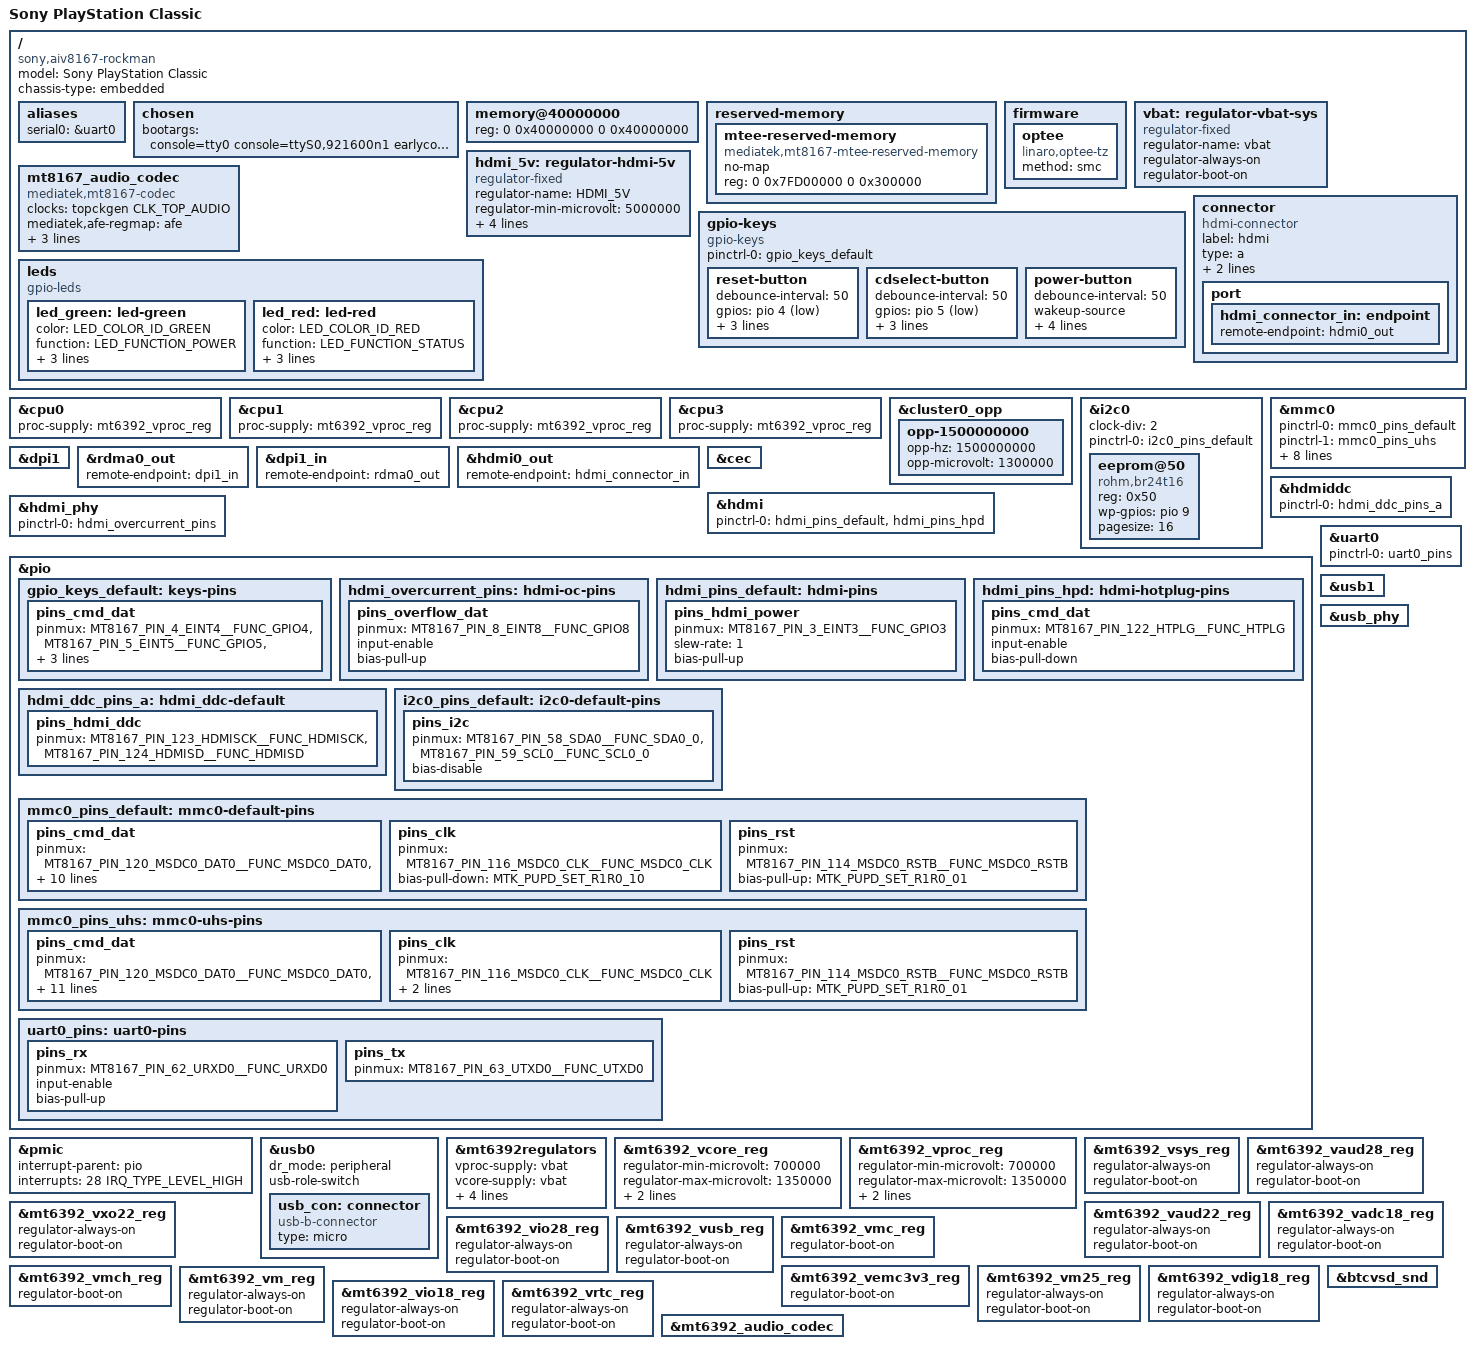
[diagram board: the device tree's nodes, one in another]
// SPDX-License-Identifier: GPL-2.0
/dts-v1/;
#include <dt-bindings/gpio/gpio.h>
#include <dt-bindings/input/linux-event-codes.h>
#include <dt-bindings/leds/common.h>
#include "mt8167.dtsi"
#include "mt6392.dtsi"

/ {
	model = "Sony PlayStation Classic";
	chassis-type = "embedded";
	compatible = "sony,aiv8167-rockman", "mediatek,mt8167";

	aliases {
		serial0 = &uart0;
	};

	chosen {
		#address-cells = <2>;
		#size-cells = <2>;
		bootargs = "console=tty0 console=ttyS0,921600n1 earlycon=uart8250,mmio32,0x11005000 root=/dev/ram0 initrd=0x42200000,4M";
		ranges;
	};

	memory@40000000 {
		device_type = "memory";
		reg = <0 0x40000000 0 0x40000000>;
	};

	reserved-memory {
		#address-cells = <2>;
		#size-cells = <2>;
		ranges;

		/*
		If you modify the memory size,please modify mtee-reserved-memory size together.
		mtee must be located begin with the last 3MB of dram
		*/
		mtee-reserved-memory {
			compatible = "mediatek,mt8167-mtee-reserved-memory";
			no-map;
			reg = <0 0x7FD00000 0 0x300000>;
		};
	};

	firmware {
		optee {
			compatible = "linaro,optee-tz";
			method = "smc";
		};
	};

	vbat: regulator-vbat-sys {
		compatible = "regulator-fixed";
		regulator-name = "vbat";
		regulator-always-on;
		regulator-boot-on;
	};

	hdmi_5v: regulator-hdmi-5v {
		compatible = "regulator-fixed";

		regulator-name = "HDMI_5V";
		regulator-min-microvolt = <5000000>;
		regulator-max-microvolt = <5000000>;

		gpio = <&pio 3 GPIO_ACTIVE_HIGH>;
		enable-active-high;
		regulator-always-on;
	};

	mt8167_audio_codec: mt8167_audio_codec {
		compatible = "mediatek,mt8167-codec";
		clocks = <&topckgen CLK_TOP_AUDIO>;
		clock-names = "bus";
		mediatek,afe-regmap = <&afe>;
		mediatek,apmixedsys-regmap = <&apmixedsys>;
		mediatek,dmic-wire-mode = <1>; /* 0(ONE_WIRE) 1(TWO_WIRE) */
		mediatek,headphone-cap-sel = <1>; /* 0(10UF) 1(22UF) 2(33UF) 3(47UF) */
	};

	/*sound {
		compatible = "mediatek,mt8167s-es7243";
		mediatek,platform = <&afe>;
		pinctrl-0 = <&aud_default_pins>;
		pinctrl-1 = <&aud_extamp_on_pins>;
		pinctrl-2 = <&aud_extamp_off_pins>;
		pinctrl-names = "default", "extamp_on", "extamp_off";
		tdmadc-3p3v-supply = <&mt6392_vmch_reg>;
		tdmadc-1p8v-supply = <&mt6392_vcamio_reg>;
	};*/

	/*extcon_usb: extcon_iddig {
		compatible = "linux,extcon-usb-gpio";
		id-gpios = <&pio 41 GPIO_ACTIVE_HIGH>;
	};*/

	gpio-keys {
		compatible = "gpio-keys";
		pinctrl-names = "default";
		pinctrl-0 = <&gpio_keys_default>;

		reset-button {
			debounce-interval = <50>;
			gpios = <&pio 4 GPIO_ACTIVE_LOW>;
			label = "playpause";
			linux,input-type = <EV_KEY>;
			linux,code = <KEY_PLAYPAUSE>;
		};

		cdselect-button {
			debounce-interval = <50>;
			gpios = <&pio 5 GPIO_ACTIVE_LOW>;
			label = "cdselect";
			linux,input-type = <EV_KEY>;
			linux,code = <KEY_EJECTCD>;
		};

		power-button {
			debounce-interval = <50>;
			wakeup-source;
			gpios = <&pio 10 GPIO_ACTIVE_LOW>;
			label = "sleep";
			linux,input-type = <EV_KEY>;
			linux,code = <KEY_SLEEP>;
		};
	};

	leds {
		compatible = "gpio-leds";

		led_green: led-green {
			color = <LED_COLOR_ID_GREEN>;
			function = LED_FUNCTION_POWER;
			gpios = <&pio 12 GPIO_ACTIVE_HIGH>;
			default-state = "off";
			retain-state-suspended;
		};

		led_red: led-red {
			color = <LED_COLOR_ID_RED>;
			function = LED_FUNCTION_STATUS;
			gpios = <&pio 0 GPIO_ACTIVE_HIGH>;
			default-state = "off";
			retain-state-suspended;
		};
	};

	connector {
		compatible = "hdmi-connector";
		label = "hdmi";

		type = "a";
		ddc-i2c-bus = <&hdmiddc>;
		hpd-gpios = <&pio 122 GPIO_ACTIVE_HIGH>;

		port {
			hdmi_connector_in: endpoint {
				remote-endpoint = <&hdmi0_out>;
			};
		};
	};
};

/* With the firmware on Android devices, cores don't seem to come back after out
   idle/unplug (though initial SMP boot is fine) */

&cpu0 {
	/delete-property/ cpu-idle-states;
	proc-supply = <&mt6392_vproc_reg>;
};

&cpu1 {
	/delete-property/ cpu-idle-states;
	proc-supply = <&mt6392_vproc_reg>;
};

&cpu2 {
	/delete-property/ cpu-idle-states;
	proc-supply = <&mt6392_vproc_reg>;
};

&cpu3 {
	/delete-property/ cpu-idle-states;
	proc-supply = <&mt6392_vproc_reg>;
};

&cluster0_opp {
	opp-1500000000 {
		opp-hz = /bits/ 64 <1500000000>;
		opp-microvolt = <1300000>;
	};
};

&i2c0 {
	clock-div = <2>;
	pinctrl-names = "default";
	pinctrl-0 = <&i2c0_pins_default>;
	status = "okay";

	eeprom@50 {
		reg = <0x50>;
		compatible = "rohm,br24t16", "atmel,24c16";
		wp-gpios = <&pio 9 GPIO_ACTIVE_HIGH>;
		pagesize = <16>;
	};
};

&mmc0 {
	status = "okay";

	pinctrl-names = "default", "state_uhs";
	pinctrl-0 = <&mmc0_pins_default>;
	pinctrl-1 = <&mmc0_pins_uhs>;

	bus-width = <8>;
	max-frequency = <200000000>;
	cap-mmc-highspeed;
	mmc-hs200-1_8v;
	cap-mmc-hw-reset;
	non-removable;

	vmmc-supply = <&mt6392_vemc3v3_reg>;
	vqmmc-supply = <&mt6392_vio18_reg>;
};

&dpi1 {
	status = "okay";
};

&rdma0_out {
	remote-endpoint = <&dpi1_in>;
};

&dpi1_in {
	remote-endpoint = <&rdma0_out>;
};

&hdmi0_out {
	remote-endpoint = <&hdmi_connector_in>;
};

&cec {
	status = "okay";
};

&hdmi {
	status = "okay";
	pinctrl-names = "default";
	pinctrl-0 = <&hdmi_pins_default>, <&hdmi_pins_hpd>;
};

&hdmiddc {
	status = "okay";
	pinctrl-names = "default";
	pinctrl-0 = <&hdmi_ddc_pins_a>;
};

&hdmi_phy {
	status = "okay";
	pinctrl-names = "default";
	pinctrl-0 = <&hdmi_overcurrent_pins>;
};

&pio {
	pinctrl-names = "default";
	/*pinctrl-0 = <&state_default>;*/

	/*state_default: default-pins {
		pins_cmd_dat1 {
			pinmux = <MT8167_PIN_1_EINT1__FUNC_GPIO1>,
				 <MT8167_PIN_2_EINT2__FUNC_GPIO2>;
			input-enable;
			bias-disable;
		};

		pins_cmd_dat2 {
			pinmux = <MT8167_PIN_6_EINT6__FUNC_GPIO6>,
				 <MT8167_PIN_7_EINT7__FUNC_GPIO7>;
			input-enable;
			bias-pull-up;
		};
	};*/

	gpio_keys_default: keys-pins {
		pins_cmd_dat {
			pinmux = <MT8167_PIN_4_EINT4__FUNC_GPIO4>,
				 <MT8167_PIN_5_EINT5__FUNC_GPIO5>,
				 <MT8167_PIN_10_EINT10__FUNC_GPIO10>;
			bias-pull-up;
			input-enable;
		};
	};

	hdmi_overcurrent_pins: hdmi-oc-pins {
		pins_overflow_dat {
			pinmux = <MT8167_PIN_8_EINT8__FUNC_GPIO8>;
			input-enable;
			bias-pull-up;
		};
	};

	hdmi_pins_default: hdmi-pins {
		pins_hdmi_power {
			pinmux = <MT8167_PIN_3_EINT3__FUNC_GPIO3>;
			slew-rate = <1>;
			bias-pull-up;
		};
	};

	hdmi_pins_hpd: hdmi-hotplug-pins {
		pins_cmd_dat {
			pinmux = <MT8167_PIN_122_HTPLG__FUNC_HTPLG>;
			input-enable;
			bias-pull-down;
		};
	};

	hdmi_ddc_pins_a: hdmi_ddc-default {
		pins_hdmi_ddc {
			pinmux = <MT8167_PIN_123_HDMISCK__FUNC_HDMISCK>,
				 <MT8167_PIN_124_HDMISD__FUNC_HDMISD>;
		};
	};

	i2c0_pins_default: i2c0-default-pins {
		pins_i2c {
			pinmux = <MT8167_PIN_58_SDA0__FUNC_SDA0_0>,
				 <MT8167_PIN_59_SCL0__FUNC_SCL0_0>;
			bias-disable;
		};
	};

	mmc0_pins_default: mmc0-default-pins {
		pins_cmd_dat {
			pinmux = <MT8167_PIN_120_MSDC0_DAT0__FUNC_MSDC0_DAT0>,
				 <MT8167_PIN_119_MSDC0_DAT1__FUNC_MSDC0_DAT1>,
				 <MT8167_PIN_118_MSDC0_DAT2__FUNC_MSDC0_DAT2>,
				 <MT8167_PIN_117_MSDC0_DAT3__FUNC_MSDC0_DAT3>,
				 <MT8167_PIN_113_MSDC0_DAT4__FUNC_MSDC0_DAT4>,
				 <MT8167_PIN_112_MSDC0_DAT5__FUNC_MSDC0_DAT5>,
				 <MT8167_PIN_111_MSDC0_DAT6__FUNC_MSDC0_DAT6>,
				 <MT8167_PIN_110_MSDC0_DAT7__FUNC_MSDC0_DAT7>,
				 <MT8167_PIN_115_MSDC0_CMD__FUNC_MSDC0_CMD>;
			input-enable;
			bias-pull-up = <MTK_PUPD_SET_R1R0_01>;
		};

		pins_clk {
			pinmux = <MT8167_PIN_116_MSDC0_CLK__FUNC_MSDC0_CLK>;
			bias-pull-down = <MTK_PUPD_SET_R1R0_10>;
		};

		pins_rst {
			pinmux = <MT8167_PIN_114_MSDC0_RSTB__FUNC_MSDC0_RSTB>;
			bias-pull-up = <MTK_PUPD_SET_R1R0_01>;
		};
	};

	mmc0_pins_uhs: mmc0-uhs-pins {
		pins_cmd_dat {
			pinmux = <MT8167_PIN_120_MSDC0_DAT0__FUNC_MSDC0_DAT0>,
				 <MT8167_PIN_119_MSDC0_DAT1__FUNC_MSDC0_DAT1>,
				 <MT8167_PIN_118_MSDC0_DAT2__FUNC_MSDC0_DAT2>,
				 <MT8167_PIN_117_MSDC0_DAT3__FUNC_MSDC0_DAT3>,
				 <MT8167_PIN_113_MSDC0_DAT4__FUNC_MSDC0_DAT4>,
				 <MT8167_PIN_112_MSDC0_DAT5__FUNC_MSDC0_DAT5>,
				 <MT8167_PIN_111_MSDC0_DAT6__FUNC_MSDC0_DAT6>,
				 <MT8167_PIN_110_MSDC0_DAT7__FUNC_MSDC0_DAT7>,
				 <MT8167_PIN_115_MSDC0_CMD__FUNC_MSDC0_CMD>;
			input-enable;
			drive-strength = <MTK_DRIVE_6mA>;
			bias-pull-up = <MTK_PUPD_SET_R1R0_01>;
		};

		pins_clk {
			pinmux = <MT8167_PIN_116_MSDC0_CLK__FUNC_MSDC0_CLK>;
			drive-strength = <MTK_DRIVE_8mA>;
			bias-pull-down = <MTK_PUPD_SET_R1R0_10>;
		};

		pins_rst {
			pinmux = <MT8167_PIN_114_MSDC0_RSTB__FUNC_MSDC0_RSTB>;
			bias-pull-up = <MTK_PUPD_SET_R1R0_01>;
		};
	};

	uart0_pins: uart0-pins {
		pins_rx {
			pinmux = <MT8167_PIN_62_URXD0__FUNC_URXD0>;
			input-enable;
			bias-pull-up;
		};
		pins_tx {
			pinmux = <MT8167_PIN_63_UTXD0__FUNC_UTXD0>;
		};
	};
};

&pmic {
	interrupt-parent = <&pio>;
	interrupts = <28 IRQ_TYPE_LEVEL_HIGH>;
};

&uart0 {
	status = "okay";

	pinctrl-names = "default";
	pinctrl-0 = <&uart0_pins>;
};

&usb0 {
	status = "okay";
	dr_mode = "peripheral";
	usb-role-switch;

	//vusb33-supply = <&mt6392_vusb_reg>;

	usb_con: connector {
		compatible = "usb-b-connector";
		type = "micro";
	};
};

&usb1 {
	status = "okay";
};

&usb_phy {
	status = "okay";
};

&mt6392regulators {
	vproc-supply = <&vbat>;
	vcore-supply = <&vbat>;
	vsys-supply = <&vbat>;
	ldo1-supply = <&vbat>;
	ldo2-supply = <&vbat>;
	ldo3-supply = <&vbat>;
};

&mt6392_vcore_reg {
	regulator-min-microvolt = <700000>;
	regulator-max-microvolt = <1350000>;
	regulator-always-on;
	regulator-boot-on;
};

&mt6392_vproc_reg {
	regulator-min-microvolt = <700000>;
	regulator-max-microvolt = <1350000>;
	regulator-always-on;
	regulator-boot-on;
};

&mt6392_vsys_reg {
	regulator-always-on;
	regulator-boot-on;
};

&mt6392_vaud28_reg {
	regulator-always-on;
	regulator-boot-on;
};

&mt6392_vxo22_reg {
	regulator-always-on;
	regulator-boot-on;
};

&mt6392_vaud22_reg {
	regulator-always-on;
	regulator-boot-on;
};

&mt6392_vadc18_reg {
	regulator-always-on;
	regulator-boot-on;
};

&mt6392_vio28_reg {
	regulator-always-on;
	regulator-boot-on;
};

&mt6392_vusb_reg {
	regulator-always-on;
	regulator-boot-on;
};

&mt6392_vmc_reg {
	regulator-boot-on;
};

&mt6392_vmch_reg {
	regulator-boot-on;
};

&mt6392_vemc3v3_reg {
	regulator-boot-on;
};

&mt6392_vm25_reg {
	regulator-always-on;
	regulator-boot-on;
};

&mt6392_vdig18_reg {
	regulator-always-on;
	regulator-boot-on;
};

&mt6392_vm_reg {
	regulator-always-on;
	regulator-boot-on;
};

&mt6392_vio18_reg {
	regulator-always-on;
	regulator-boot-on;
};

&mt6392_vrtc_reg {
	regulator-always-on;
	regulator-boot-on;
};

&btcvsd_snd {
	status = "okay";
};

&mt6392_audio_codec {
	status = "okay";
};
